# STM32MP25_CM33 register map
File version: 1.3
CPU: CM33 r0p1, little endian, MPU, FPU, vendor SysTick, 8 interrupt priority bits
Registers are 32-bit, read-write, reset 0x0 unless marked. A register's access mark holds for its fields unless they carry their own. Offsets are from the block's base; [hi:lo] are bit positions; lines under a group give offsets from that group; {n}, {i} and the like mark numbered series; 'fields as' and 'values as' point back to an identical list.

## I3C1 (part 1 of 2) — I3C register block
Base 0x40190000
Same registers: I3C2 0x401A0000, I3C3 0x401B0000, I3C4 0x46080000, I3C1_S 0x50190000, I3C2_S 0x501A0000, I3C3_S 0x501B0000, I3C4_S 0x56080000
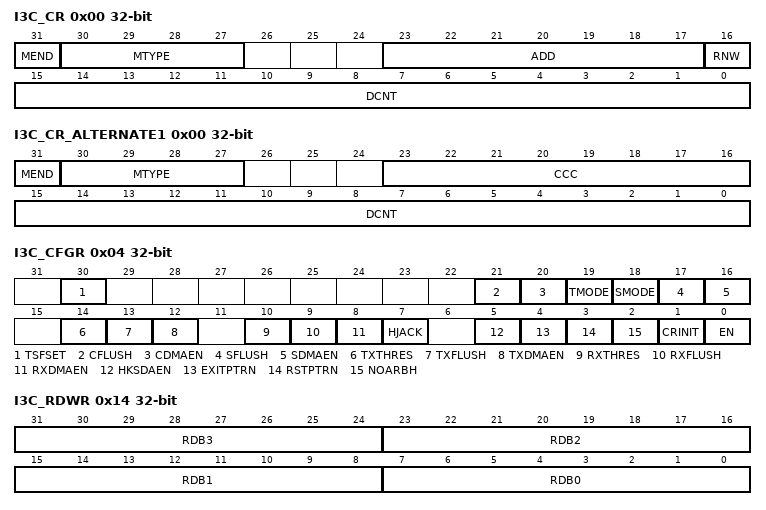
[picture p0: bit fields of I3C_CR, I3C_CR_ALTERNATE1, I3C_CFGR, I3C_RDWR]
0x00 I3C_CR wo — I3C message control register
  [31] MEND — Message end type/last message of a frame (when the I3C acts as controller)
    0=this message from controller is followed by a repeated start (Sr), before another message must be emitted; 1=this message from controller ends with a stop (P), being the last message of a frame
  [30:27] MTYPE — Message type (whatever I3C acts as controller/target) Bits[26:0] are ignored. On a CE1 error detection (ERRF = 1 in the I3C_EVR register and CODERR[3:0] = 0001 in the I3C_SER register) where a start/restart/stop is prevented from being generated, the software must use this message type for SCL “stuck at” recovery. Refer to Table 760. Bits[26:0] are ignored. If the addressed target is not responding with an ACK to a private/direct message, as an escalation stage after a failed GETSTATUS tentative, the software must program this with EXITPTRN = 1 in the I3C_CFGR register, so that an HDR exit pattern is emitted on the bus, whatever the header is ACK-ed or NACK-ed (to avoid the target to consider that the I3C bus is in HDR mode). Refer to Table760 and MIPI specification about escalation handling. Bits[23:17] (ADD[6:0]) are the emitted 7-bit dynamic address. Bit[16] (RNW) is the emitted RnW bit. Bits[15:0] (DCNT[15:0]) are the number of programmed data bytes. The transferred private message is: {S / S + 0b111_1110 + RnW = 0 + Sr/Sr+*} + 7-bit DynAddr + RnW + (8-bit Data + T)* + Sr/P. After an S (start), depending upon bit NOARBH in the I3C_CFGR register, the arbitrable header (0b111_1110 + RnW = 0) is inserted or not. Sr+*: after an Sr (repeated start), the hardware automatically inserts (0b111_1110 + RnW = 0) if needed, if it follows a previous message without ending by a P (stop). Bits[23:17] (ADD[6:0]) are the emitted 7-bit dynamic address. Bit[16] (RNW) is the emitted RnW bit. Bits[15:0] (DCNT[15:0]) are the number of programmed data bytes. The transferred direct message is: Sr + 7-bit DynAddr + RnW + (8-bit Data + T)* + Sr/P Bits[23:17] (ADD[6:0]) are the emitted 7-bit static address. Bit[16] (RNW) is the emitted RnW bit. Bits[15:0] (DCNT[15:0]) are the number of programmed data bytes. The transferred legacy Isup2/supC message is: {S / S + 0b111_1110 + RnW = 0 + Sr/Sr+*} + 7-bit StaAddr + RnW + (8-bit data + T)* + Sr/P. After an S, depending on NOARBH, the arbitrable header (0b111_1110 + RnW = 0) is inserted or not. Sr+*: after an Sr (repeated start), the hardware automatically inserts (0b111_1110 + RnW = 0) if needed (if it follows a previous message without ending by a P (stop)). Others: reserved The transferred hot-join request is {S +} 0b000_0010 addr + RnW = 0. Writing the control word initiates the hot-join request if target is allowed to do so (HJEN = 1 in the I3C_DEVR0 register), either actively after a bus idle condition via the hardware issuing a start request (SDA low) and waiting for the controller to activate SCL clock, or passively if the controller initiates a concurrent message. The transferred controller-role request is {S +} DA[6:0] + RnW = 0 (DA in the I3C_DEVR0 register) Writing the control word initiates the controller-role request if target is allowed to do so (CREN = 1 and DAVAL = 1 in the I3C_DEVR0 register), either actively after a bus idle condition via the hardware issuing a start request (SDA low) and waiting for the controller to activate SCL clock, or passively if the controller initiates a concurrent message. Bits[15:0] (DCNT[15:0]) are the number of the IBI data payload (including the first MDB), if any. The transferred IBI request is {S +} DA[6:0] + RnW = 1 + optional IBI data payload. Writing the control word initiates the IBI request if target is allowed to do so (IBIEN = 1 and DAVAL = 1 in the I3C_DEVR0.register), either actively after a bus idle condition via the hardware issuing a start request (SDA low) and waiting for the controller to activate SCL clock, or passively if the controller initiates a concurrent message. When acknowledged from controller, the transmitted IBI payload data (optional, depending upon BCR2 in the I3C_BCR register) is defined by DCNT[15:0] in the I3C_CR register and I3C_IBIDR, and must be consistently programmed vs. the IBI payload data size defined by IBIP[2:0] in the I3C_IBIDR register. Others: reserved
    0=B_0x0_WHEN_I3C_ACTS_AS_I3C_CONTROLLER (SCL clock is forced to stop until a next control word is executed); 1=B_0x1_WHEN_I3C_ACTS_AS_I3C_CONTROLLER (header message); 2=B_0x2_WHEN_I3C_ACTS_AS_I3C_CONTROLLER (private message (refer to Figure906)); 3=B_0x3_WHEN_I3C_ACTS_AS_I3C_CONTROLLER (direct message (second part of an I3C SDR direct CCC command) (refer to Figure899)); 4=B_0x4_WHEN_I3C_ACTS_AS_I3C_CONTROLLER (legacy Isup2/supC message (refer to Figure908)); 8=B_0x8_WHEN_I3C_ACTS_AS_I3C_TARGET (hot-join request (W) (refer to Figure910)); 9=B_0x9_WHEN_I3C_ACTS_AS_I3C_TARGET (controller-role request (W) (refer to Figure911)); 10=B_0xA_WHEN_I3C_ACTS_AS_I3C_TARGET (IBI (in-band interrupt) request (R) (refer to Figure909))
  [23:17] ADD — 7-bit I3C dynamic / Isup2/supC static target address (when I3C acts as controller) When I3C acts as controller, this field is used if MTYPE[3:0] = 0010 (private message), or MTYPE[3:0] = 0011 (direct message), or MTYPE[3:0] = 0100 (legacy Isup2/supC message)
  [16] RNW — Read / non-write message (when I3C acts as controller) When I3C acts as controller, this field is used if MTYPE[3:0] = 0010 (private message), or MTYPE[3:0] = 0011 (direct message), or MTYPE[3:0] = 0100 (legacy Isup2/supC message), to emit the RnW bit on the I3C bus.
    0=write message; 1=read message
  [15:0] DCNT — Count of data to transfer during a read or write message, in bytes (whatever I3C acts as controller/target) When I3C acts as controller, this field is used if MTYPE[3:0] = 0010 (private message), or MTYPE[3:0] = 0011 (direct message), or MTYPE[3:0] = 0100 (legacy Isup2/supC message), to set the number of exchanged data bytes on the bus. In case of a private or legacy Isup2/supC read/write message, this field must be non-null. When I3C acts as target, this field is used if MTYPE[3:0] = 1010 (IBI request) and if any IBI data payload (data to be transmitted if BCR2 = 1 in the I3C_BCR register), to set the number of bytes of the IBI data payload (1, 2, 3, or 4). Linear encoding up to 64Kbytes - 1 ...
    0=no data to transfer; 1=1 byte; 2=2 bytes; 0xFFFF=64 Kbytes - 1 byte
0x00 I3C_CR_ALTERNATE1 wo (alternate view of I3C_CR) — I3C message control register
  [31] MEND — Message end type/last message of a frame (when I3C acts as controller)
    0=this message from controller is followed by a repeated start (Sr), before another message must be emitted; 1=the message from the controller ends with a stop (P), being the last message of a frame
  [30:27] MTYPE — Message type (when I3C acts as controller) Bits[23:16] (CCC[7:0]) are the emitted 8-bit CCC code Bits[15:0] (DCNT[15:0]) are the number of the CCC defining bytes, or CCC sub-command bytes, or CCC data bytes. If Bit[23] = CCC[7] = 1: this is the first part of an I3C SDR direct CCC command The transferred direct CCC command (first part) message is: {S / S + 0b111_1110 +RnW = 0 / Sr+*} + (direct CCC + T) + (8-bit Data + T)* + Sr After an S (start), depending upon NOARBH in the I3C_CFGR register, the arbitrable header (0b111_1110+RnW = 0) is inserted or not. Sr+*: after an Sr (repeated start), the hardware automatically inserts (0b111_1110 + R/W). If Bit[23] = CCC[7] = 0: this is an I3C SDR broadcast CCC command (including specific ENTDAA, refer to Figure900) The transferred broadcast CCC command message is: {S / S + 0b111_1110 + RnW = 0 / Sr+*} + (broadcast CCC + T) + (8-bit Data + T)* + Sr/P After an S (start), depending on NOARBH, the arbitrable header (0b111_1110+RnW=0) is inserted or not. Sr+*: after an Sr (repeated start), the hardware automatically inserts (0b111_1110 + R/W). Others: reserved
    6=B_0x6_WHEN_I3C_ACTS_AS_I3C_CONTROLLER (broadcast/direct CCC command (refer to Table759, Figure899, Figure900, Figure901))
  [23:16] CCC — 8-bit CCC code (when I3C acts as controller) If bit[23] = CCC[7] = 1, this is the first part of an I3C SDR direct CCC command. If bit[23] = CCC[7] = 0, this is an I3C SDR broadcast CCC command (including ENTDAA).
  [15:0] DCNT — Count of related data to the CCC command to transfer as CCC defining bytes, or CCC sub-command bytes, or CCC data bytes, in bytes Linear encoding up to 64Kbytes - 1. Note: Value mandatory when emitting ENTDAA broadcast CCC (refer to Figure900). Note: Value mandatory when emitting RSTACT direct/broadcast CCC (refer to Figure901). ...
    values as I3C_CR.DCNT
0x04 I3C_CFGR — I3C configuration register
  [30] TSFSET wo — Frame transfer set (software trigger) (when I3C acts as controller) This bit can only be written. When I3C acts as I3C controller: Note: If this bit is not set, the other alternative for the software to initiate a frame transfer is to directly write the first control word register (I3C_CR) while C-FIFO is empty (CFEF = 1 in the I3C_EVR register). Then, if the first written control word is not tagged as a message end (MEND = 0 in the I3C_CR register), it causes the hardware to assert CFNFF.
    0=no action; 1=setting this bit initiates a frame transfer by causing the hardware to assert the flag CFNFF in the I3C_EVR register (C-FIFO not full and a control word is needed)
  [21] CFLUSH wo — C-FIFO flush (when I3C acts as controller) This bit can only be written.
    0=no action; 1=flush C-FIFO
  [20] CDMAEN — C-FIFO DMA request enable (when I3C acts as controller) When I3C acts as controller: - Software writes and pushes control word(s) into C-FIFO (writes I3C_CR register), as needed for a given frame - A next control word transfer can be written by software either via polling on the flag CFNFF = 1 in the I3C_EVR register, or via interrupt notification (enabled by CFNFIE = 1 in the I3C_IER register). - DMA writes and pushes control word(s) into C-FIFO (writes I3C_CR register), as needed for a given frame. - A next control word transfer is automatically written by the programmed hardware (via the asserted C-FIFO DMA request from the I3C and the programmed DMA channel).
    0=DMA mode is disabled for C-FIFO; 1=DMA mode is enabled for C-FIFO
  [19] TMODE — Transmit mode (when I3C acts as controller) When I3C acts as controller, this bit is used for the C-FIFO and TX-FIFO management vs. the emitted frame on the I3C bus. A frame transfer starts as soon as the first control word is present in C-FIFO.
    0=C-FIFO and TX-FIFO are not preloaded before starting to emit a frame transfer; 1=C-FIFO and TX-FIFO are first preloaded (also TX-FIFO if needed, depending on the frame format) before starting to emit a frame transfer. Refer to Section76.10.2 for more details.
  [18] SMODE — S-FIFO enable / status receive mode (when I3C acts as controller) When I3C acts as controller, this bit is used to enable the FIFO for the status (S-FIFO) of the exchanged message on the I3C bus. When I3C acts as target, this bit must be cleared. - Status register (I3C_SR) is used without FIFO mechanism. - There is no SCL stalling if a new status register content is not read. - Status register must be read before being overwritten by the hardware. - Must have SDMAEN = 0 in the I3C_CFGR register. - Each message status must be read. - There is SCL stalling when the S-FIFO is full and a next message status must be read. - S-FIFO overrun error is reported after the maximum SCL clock stalling time.
    0=S-FIFO is disabled; 1=S-FIFO is enabled
  [17] SFLUSH wo — S-FIFO flush (when I3C acts as controller) This bit can be written and used only when I3C acts as controller.
    0=no action; 1=flush S-FIFO
  [16] SDMAEN — S-FIFO DMA request enable (when I3C acts as controller) This bit must be cleared if SMODE = 0 in the I3C_CFGR register (S-FIFO is disabled). In other words, DMA mode cannot be used if S-FIFO is disabled. Then the status register I3C_SR can be read or not. This bit can be set or cleared if SMODE = 1 (S-FIFO is enabled). In other words, status register I3C_SR must be read for each message, either by software, or via an allocated DMA channel. - SMODE = 0: software can read the I3C_SR register after a completed frame (FCF = 1 in the I3C_EVR register) or an error (ERRF = 1 in the I3C_EVR register). Via polling on these register flags or via interrupt notification (enabled by FCIE = 1 and ERRIE=1 in the I3C_IER register). - SMODE = 1: software must read and pop a status word from S-FIFO (read I3C_SR register) after each asserted flag SFNEF = 1. Via polling on this register flag or via interrupt notification (enabled by SFNEIE = 1 in the I3C_IER register). - Must have SMODE = 1 in the I3C_CFGR register (S-FIFO enabled) - DMA reads and pops status word(s) from S-FIFO (it reads I3C_SR register) - Status word(s) are automatically read by the programmed hardware (via the asserted S-FIFO DMA request from the I3C and the programmed DMA channel).
    0=DMA mode is disabled for reading status register I3C_SR; 1=DMA mode is enabled for reading status register I3C_SR
  [14] TXTHRES — TX-FIFO threshold (whatever I3C acts as controller/target) This threshold defines, compared to the TX-FIFO level, when the TXFNFF flag is set in the I3C_EVR register (and consequently if TXDMAEN = 1 when is asserted a DMA TX request). TXFNFF is set when 1 byte must be written in TX-FIFO (in I3C_TDR). TXFNFF is set when 1 word / 4 bytes must be written in TX-FIFO (in the I3C_TDWR register). If the a number of the last transmitted data is not a multiple of 4 bytes (XDCNT[1:0] = 00 in the I3C_SR register), only the relevant 1, 2, or 3 valid LSB bytes of the last word are taken into account by the hardware, and sent on the I3C bus.
    0=1-byte threshold; 1=1-word / 4-byte threshold
  [13] TXFLUSH wo — TX-FIFO flush (whatever I3C acts as controller/target) This bit can only be written. When the I3C acts as target, this bit can be used to flush the TX-FIFO on a private read if the controller has aborted the data read (driven low the T bit), and there is/are remaining data in the TX-FIFO (ABT = 1, and XDCNT[15:0] in the I3C_SR register TGTTDCNT[15:0] in the I3C_TGTTDR register).
    0=no action; 1=flush TX-FIFO
  [12] TXDMAEN — TX-FIFO DMA request enable (whatever I3C acts as controller/target) - Software writes and pushes a data byte/word into TX-FIFO (writes I3C_TDR or I3C_TDWR register), to be transmitted over the I3C bus. - A next data byte/word must be written by the software either via polling on the flag TXFNFF = 1 or via interrupt notification (enabled by TXFNFIE = 1). - DMA writes and pushes data byte(s)/word(s) into TX-FIFO (writes I3C_TDR or I3C_TDWR register). - A next data byte/word transfer is automatically pushed by the programmed hardware (via the asserted TX-FIFO DMA request from the I3C and the programmed DMA channel).
    0=DMA mode is disabled for TX-FIFO; 1=DMA mode is enabled for TX-FIFO
  [10] RXTHRES — RX-FIFO threshold (whatever I3C acts as controller/target) This threshold defines, compared to the RX-FIFO level, when the RXFNEF flag in the I3C_EVR register is set (and consequently if RXDMAEN = 1 when is asserted a DMA RX request). RXFNEF is set when 1 byte must be read in RX-FIFO (in the I3C_RDR register). RXFNEF is set when 1 word / 4 bytes is/are to be read in RX-FIFO (in I3C_RDWR). In the case of a number of last received data being not a multiple of 4 bytes, only the relevant 1, 2 or 3 valid LSB bytes of the last word are to be considered by the software. The number of effective received data bytes is reported by XDCNT[15:0] in the I3C_SR register.
    0=1-byte threshold; 1=1-word/4-bytes threshold
  [9] RXFLUSH wo — RX-FIFO flush (whatever I3C acts as controller/target) This bit can only be written.
    0=no action; 1=flush RX-FIFO
  [8] RXDMAEN — RX-FIFO DMA request enable (whatever I3C acts as controller/target) - Software reads and pops a data byte/word from RX-FIFO (it reads I3C_RDR or I3C_RDWR register). - A next data byte/word must be read by the software either via polling flag RXFNEF = 1 in the I3C_EVR register, or via interrupt notification (enabled by RXFNEIE = 1 in the I3C_IER register). - DMA reads and pops data byte(s)/word(s) from RX-FIFO (reads I3C_RDR or I3C_RDWR register). - A next data byte/word is automatically read by the programmed hardware (via the asserted RX-FIFO DMA request from the I3C and the programmed DMA channel).
    0=DMA mode is disabled for RX-FIFO; 1=DMA mode is enabled for RX-FIFO
  [7] HJACK — Hot-join request acknowledge (when I3C acts as a controller) After the NACK, the controller continues as initially programmed (the hot-joining target is aware of the NACK and must emit another hot-join request later on). After the ACK, the controller continues as initially programmed. The software is notified by the HJ interrupt (flag HJF is set in the I3C_EVR register), and must initiate the ENTDAA sequence later on, potentially preventing other hot-join requests with a disable target events command (DISEC, with DISHJ = 1).
    0=hot-join request is not acknowledged; 1=hot-join request is acknowledged
  [5] HKSDAEN — High-keeper enable on SDA line (when I3C acts as a controller) Note: This bit can be modified only when EN = 0 in the I3C_CFGR register.
    0=High-keeper is disabled; 1=High-keeper is enabled, and the weak pull-up is effective on the T bit, instead of the open-drain class pull-up
  [4] EXITPTRN — HDR exit pattern enable (when I3C acts as a controller) This bit can be modified only when there is no on-going frame. The HDR exit pattern is sent whatever the message header {S/Sr + 0x7E addr + W} is ACK-ed or NACK-ed..
    0=HDR exit pattern is not sent after the issued message header (MTYPE[3:0]=0001 in the I3C_CR register). This is used to send the header, to test ownership of the bus when there is a suspicion of a problem after controller-role hand-off (new controller did not assert its controller-role by accessing the previous one in less than the delay defined by the activity state).; 1=HDR exit pattern is sent after the issued message header (MTYPE[3:0]=0001). This is used on a controller error detection and escalation handling, in case of a not responding target to a private message or a direct read CCC.
  [3] RSTPTRN — HDR reset pattern enable (when I3C acts as a controller) This bit can be modified only when there is no on-going frame.
    0=standard stop emitted at the end of a frame; 1=HDR reset pattern is inserted before the stop of any emitted frame that includes a RSTACT CCC command
  [2] NOARBH — No arbitrable header after a start (when I3C acts as a controller) This bit can be modified only when there is no on-going frame. - The target address is emitted directly after a start in case of a legacy Isup2/supC message or an I3C SDR private read/write message. - This is a more performing option (when the emission of the 0x7E arbitrable header is useless), but must be used only when the controller is sure that the addressed target device cannot emit concurrently an IBI or a controller-role request (to insure no misinterpretation and no potential conflict between the address emitted by the controller in open-drain mode and the same address a target device can emit after a start, for IBI or MR).
    0=An arbitrable header (0b111_1110 + RnW = 0) is emitted after a start and before a legacy Isup2/supC message or an I3C SDR private read/write message (default); 1=No arbitrable header
  [1] CRINIT — Initial controller/target role This bit can be modified only when EN=0 in the I3C_CFGR register. Once enabled by setting EN=1, the peripheral initially acts as a target. I3C does not drive SCL line and does not enable SDA pull-up, until it eventually acquires the controller role. Once enabled by setting EN=1, the peripheral initially acts as a controller. It has the I3C controller role, so drives SCL line and enables SDA pull-up, until it eventually offers the controller role to an I3C secondary controller.
    0=target role; 1=controller role
  [0] EN — I3C enable (whatever I3C acts as controller/target) - Except registers, the peripheral is under reset (partial reset). - Before clearing EN, when I3C acts as a controller, all the possible target requests must be disabled using DISEC CCC. - When I3C acts as a target, software must not disable the I3C, unless a partial reset is needed. In this state, some register fields cannot be modified (like CRINIT, HKSDAEN for the I3C_CFGR)
    0=I3C is disabled; 1=I3C is enabled
0x10 I3C_RDR ro — I3C receive data byte register
  [7:0] RDB0 — 8-bit received data on I3C bus.
0x14 I3C_RDWR ro — I3C receive data word register
  [31:24] RDB3 — 8-bit received data (latest byte on I3C bus).
  [23:16] RDB2 — 8-bit received data (next byte after RDB1 on I3C bus).
  [15:8] RDB1 — 8-bit received data (next byte after RDB0 on I3C bus).
  [7:0] RDB0 — 8-bit received data (earliest byte on I3C bus).
0x18 I3C_TDR wo — I3C transmit data byte register
  [7:0] TDB0 — 8-bit data to transmit on I3C bus.
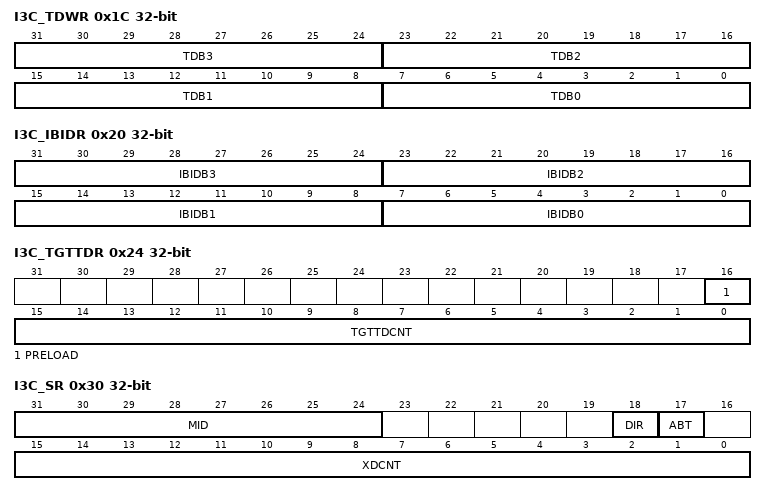
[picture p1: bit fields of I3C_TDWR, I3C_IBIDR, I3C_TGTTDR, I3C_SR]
0x1C I3C_TDWR wo — I3C transmit data word register
  [31:24] TDB3 — 8-bit transmit data (latest byte on I3C bus).
  [23:16] TDB2 — 8-bit transmit data (next byte after TDB1[7:0] on I3C bus).
  [15:8] TDB1 — 8-bit transmit data (next byte after TDB0[7:0] on I3C bus).
  [7:0] TDB0 — 8-bit transmit data (earliest byte on I3C bus)
0x20 I3C_IBIDR — I3C IBI payload data register
  [31:24] IBIDB3 — 8-bit IBI payload data (latest byte on I3C bus).
  [23:16] IBIDB2 — 8-bit IBI payload data (next byte on I3C bus after IBIDB1[7:0]).
  [15:8] IBIDB1 — 8-bit IBI payload data (next byte on I3C bus after IBIDB0[7:0]).
  [7:0] IBIDB0 — 8-bit IBI payload data (earliest byte on I3C bus, MDB[7:0] mandatory data byte).
0x24 I3C_TGTTDR — I3C target transmit configuration register
  [16] PRELOAD — Preload of the TX-FIFO (when I3C is configured as target) This bit must be written and asserted by software in the same access when is written and defined the number of bytes to preload into the TX-FIFO and to transmit. This bit is cleared by hardware when all the data bytes to transmit are loaded into the TX-FIFO.
    0=no TX-FIFO preload; 1=TX-FIFO preload
  [15:0] TGTTDCNT — Transmit data counter, in bytes (when I3C is configured as target) This bit field must be written by software in the same access when is asserted PRELOAD, in order to define the number of bytes to preload and to transmit. This bit field is updated by hardware and reports, when read, the remaining number of bytes to be loaded into the TX-FIFO.
0x30 I3C_SR ro — I3C status register
  [31:24] MID — Message identifier/counter of a given frame (when the I3C acts as controller) When I3C acts as controller, this fbitield identifies the control word message (I3C_CR) to whom the I3C_SR status register refers. First message of a frame is identified with MID[7:0] = 0. This bit field is incremented (by hardware) on the completion of a new message control word (I3C_CR) over I3C bus. This field is reset for every new frame start.
  [18] DIR — Message direction Whatever the I3C acts as controller or target, this bit indicates the direction of the related message on the I3C bus Note: ENTDAA CCC is considered as a write command.
    0=write; 1=read
  [17] ABT — A private read message is ended prematurely by the target (when the I3C acts as controller) When the I3C acts as controller, this bit indicates if the private read data transmitted by the target early terminates (the target drives T bit low earlier vs. what the controller expects in terms of programmed number of read data bytes DCNT[15:0] in the I3C_CR register).
    0=no early completion from the target; 1=early completion from the target
  [15:0] XDCNT — Data counter - When the I3C acts as controller: number of targets detected on the bus - When the I3C acts as target: number of transmitted bytes - Whatever the I3C acts as controller or target: number of data bytes read from or transmitted on the I3C bus during the message
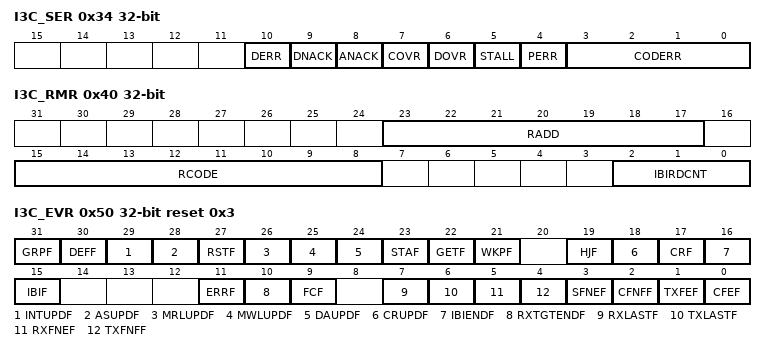
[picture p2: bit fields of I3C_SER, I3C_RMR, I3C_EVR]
0x34 I3C_SER ro — I3C status error register
  [10] DERR — Data error (when the I3C acts as controller)
    0=no detected error; 1=controller detected a data error during the controller-role hand-off procedure (GETACCCR CCC, formerly known as GETACCMST) when the received target address or/and the parity bit do no match. Active controller keeps controller-role.
  [9] DNACK — Data not acknowledged (when the I3C acts as controller) i) a legacy I2C write transfer ii) the second trial when sending dynamic address during ENTDAA procedure
    0=no detected error; 1=controller detected that a data byte is not acknowledged by a target, either during:
  [8] ANACK — Address not acknowledged (when the I3C is configured as controller) i) a legacy I2C read/write transfer ii) a direct CCC write transfer iii) the second trial of a direct CCC read transfer iv) a private read/write transfer
    0=no detected error; 1=controller detected that the static/dynamic address was not acknowledged by a target, either during:
  [7] COVR — C-FIFO underrun or S-FIFO overrun (when the I3C acts as controller) i) a C-FIFO underrun: control FIFO is empty and a restart must be emitted ii) an S-FIFO overrun: S-FIFO is full and a new message ends
    0=no detected error; 1=controller detected either:
  [6] DOVR — RX-FIFO overrun or TX-FIFO underrun i) a TX-FIFO underrun: TX-FIFO is empty and a write data byte must be transmitted ii) a RX-FIFO overrun: RX-FIFO is full and a new data byte is received
    0=no detected error; 1=whatever controller or target, hardware detected either:
  [5] STALL — SCL stall error (when the I3C acts as target)
    0=no detected error; 1=target detected that SCL was stable for more than 125 s during an I3C SDR data read (during a direct CCC read, a private read, or an IB)
  [4] PERR — Protocol error
    0=no detected error; 1=whatever controller or target, hardware detected a protocol error, as detailed in CODERR[3:0]
  [3:0] CODERR — Protocol error code/type controller detected an illegally formatted CCC controller detected that transmitted data on the bus is different from expected controller detected a not acknowledged broadcast address (0b111_1110) controller detected the new controller did not drive bus after controller-role hand-off target detected an invalid broadcast address 0b111_1110 + W target detected a parity error on a CCC code via a parity check (vs. T bit) target detected a parity error on a write data via a parity check (vs. T bit) target detected a parity error on the assigned address during dynamic address arbitration via a parity check (vs. PAR bit) target detected a 0b111_1110 + R missing after Sr during dynamic address arbitration target detected an illegally formatted CCC target detected that transmitted data on the bus is different from expected others: reserved
    0=CE0 error (transaction after sending CCC):; 1=CE1 error (monitoring error):; 2=CE2 error (no response to broadcast address):; 3=CE3 error (failed controller-role hand-off):; 8=TE0 error (invalid broadcast address 0b111_1110 + W):; 9=TE1 error (CCC code):; 10=TE2 error (write data):; 11=TE3 error (assigned address during dynamic address arbitration):; 12=TE4 error (0b111_1110 + R missing after Sr during dynamic address arbitration):; 13=TE5 error (transaction after detecting CCC):; 14=TE6 error (monitoring error):
0x40 I3C_RMR ro — I3C received message register
  [23:17] RADD — Received target address (when the I3C is configured as controller) When the I3C is configured as controller, this field logs the received dynamic address from the target during acknowledged IBI or controller-role request.
  [15:8] RCODE — Received CCC code (when the I3C is configured as target) When the I3C is configured as target, this field logs the received CCC code.
  [2:0] IBIRDCNT — IBI received payload data count (when the I3C is configured as controller) When the I3C is configured as controller, this field logs the number of data bytes effectively received in the I3C_IBIDR register.
0x50 I3C_EVR ro reset 0x3 — I3C event register
  [31] GRPF — Group addressing flag (when the I3C acts as target) When the I3C acts as target (and is typically controller-capable), this flag is asserted by hardware to indicate that the broadcast DEFGRPA CCC (define list of group addresses) has been received. Then, software can store the received data for when getting controller role. The flag is cleared when software writes 1 into the corresponding CGRPF bit in the I3C_CR register.
  [30] DEFF — DEFTGTS flag (when the I3C acts as target) When the I3C acts as target (and is typically controller capable), this flag is asserted by hardware to indicate that the broadcast DEFTGTS CCC (define list of targets) has been received. Then, software can store the received data for when getting the controller role. The flag is cleared when software writes 1 into the corresponding CDEFF bit in the I3C_CEVR register.
  [29] INTUPDF — Interrupt/controller-role/hot-join update flag (when the I3C acts as target) When the I3C acts as target, this flag is asserted by hardware to indicate that the direct or broadcast ENEC/DISEC CCC (enable/disable target events) has been received, where a target event is either an interrupt/IBI request, a controller-role request, or an hot-join request. Then, software must read respectively IBIEN, CREN, or HJEN in the I3C_DEVR0 register. The flag is cleared when software writes 1 into the corresponding CINTUPDF bit in the I3C_CEVR register.
  [28] ASUPDF — Activity state update flag (when the I3C acts as target) When the I3C acts as target, this flag is asserted by hardware to indicate that the direct or broadcast ENTASx CCC (with x = 0...3) has been received. Then, software must read AS[1:0] in the I3C_DEVR0 register. The flag is cleared when software writes 1 into the corresponding CASUPDF bit in the I3C_CEVR register.
  [27] RSTF — Reset pattern flag (when the I3C acts as target) When I3C acts as target, this flag is asserted by hardware to indicate that a reset pattern has been detected (14 SDA transitions while SCL is low, followed by repeated start, then stop). Then, when not in Stop mode, software must read RSTACT[1:0] and RSTVAL in the I3C_DEVR0 register, to know the required reset level. If RSTVAL = 1: when the RSTF is asserted (and/or the corresponding interrupt if enabled), RSTACT[1:0] in the I3C_DEVR0 register dictates the reset action to be performed by the software, if any. If RSTVAL = 0: when the RSTF is asserted (and/or the corresponding interrupt if enabled), the software must issue an I3C reset after a first detected reset pattern, and a system reset on the second one. When in Stop mode, the corresponding interrupt can be used to wake up the device. The flag is cleared when software writes 1 into the corresponding CRSTF bit in the I3C_CEVR register.
  [26] MRLUPDF — Maximum read length update flag (when the I3C acts as target) When the I3C acts as target, this flag is asserted by hardware to indicate that a direct SETMRL CCC (set max read length) has been received. Then, software must read MRL[15:0] in the I3C_MAXRLR register to get the maximum read length value. The flag is cleared when software writes 1 into the corresponding CMRLUPDF bit in the I3C_CEVR register.
  [25] MWLUPDF — Maximum write length update flag (when the I3C acts as target) When the I3C acts as target, this flag is asserted by hardware to indicate that a direct SETMWL CCC (set max write length) has been received. Then, software must read MWL[15:0] in the I3C_MAXRLR register to get the maximum write length value. The flag is cleared when software writes 1 into the corresponding CMWLUPDF bit in the I3C_CEVR register.
  [24] DAUPDF — Dynamic address update flag (when the I3C acts as target) When the I3C acts as target, this flag is asserted by hardware to indicate that a dynamic address update has been received via any of the broadcast ENTDAA, RSTDAA and direct SETNEWDA CCC. Then, software must read DA[6:0] and DAVAL in the I3C_DEVR0 register to get the dynamic address update. The flag is cleared when software writes 1 into the corresponding CDAUPDF bit in the I3C_CEVR register.
  [23] STAF — Get status flag (when the I3C acts as target) When the I3C acts as target, this flag is asserted by hardware to indicate that a direct GETSTATUS CCC of format 1 (without defining byte or with defining byte TGTSTAT) has been received. The flag is cleared when software writes 1 into the corresponding CSTAF bit in the I3C_CEVR register.
  [22] GETF — Get flag (when the I3C acts as target) When the I3C acts as target, this flag is asserted by hardware to indicate that any direct CCC of get type (GET*** CCC) except the GETSTATUS of format 1 (but including GETSTATUS of format 2) has been received. The flag is cleared when software writes 1 into the corresponding CGETF bit in the I3C_CEVR register.
  [21] WKPF — Wake-up/missed start flag (when the I3C acts as target) When the I3C acts as target, this flag is asserted by hardware to indicate that a start has been detected (an SDA falling edge followed by an SCL falling edge) but on the next SCL falling edge, the I3C kernel clock is (still) gated. Thus an I3C bus transaction may have been lost by the target. The corresponding interrupt can be used to wake up the device from a low power (Sleep or Stop) mode. The flag is cleared when software writes 1 into the corresponding CWKPF bit in the I3C_CEVR register.
  [19] HJF — Hot-join flag (when the I3C acts as controller) When the I3C acts as controller, this flag is asserted by hardware to indicate that an hot join request has been received. The flag is cleared when software writes 1 into the corresponding CHJF bit in the I3C_CEVR register.
  [18] CRUPDF — Controller-role update flag (when the I3C acts as target) When the I3C acts as target, this flag is asserted by hardware to indicate that it has now gained the controller role after the completed controller-role hand-off procedure. The flag is cleared when software writes 1 into the corresponding CCRUPDF bit in the I3C_CEVR register.
  [17] CRF — Controller-role request flag (when the I3C acts as controller) When the I3C acts as controller, this flag is asserted by hardware to indicate that a controller-role request has been acknowledged and completed (by hardware). The software must then issue a GETACCCR CCC (get accept controller role) for the controller-role hand-off procedure. The flag is cleared when software writes 1 into the corresponding CCRF bit in the I3C_CEVR register.
  [16] IBIENDF — IBI end flag (when the I3C acts as target) When the I3C acts as target, this flag is asserted by hardware to indicate that an IBI transfer has been received and completed (IBI acknowledged and IBI data bytes read by controller if any). The flag is cleared when software writes 1 into the corresponding CIBIENDF bit in the I3C_CEVR register.
  [15] IBIF — IBI flag (when the I3C acts as controller) When the I3C acts as controller, this flag is asserted by hardware to indicate that an IBI request has been received. The flag is cleared when software writes 1 into the corresponding CIBIF bit in the I3C_CEVR register.
  [11] ERRF — Flag (whatever the I3C acts as controller/target) This flag is asserted by hardware to indicate that an error occurred.Then, software must read I3C_SER to get the error type. The flag is cleared when software writes 1 into the corresponding CERRF bit in the I3C_CEVR register.
  [10] RXTGTENDF — Target-initiated read end flag (when the I3C acts as controller) When the I3C acts as controller, and only if the S-FIFO is disabled (SMODE = 0 in the I3C_CFGR register), this flag is asserted by hardware to indicate that the target has prematurely ended a read transfer. Then, software must read the status register I3C_SR to check information related to the last message and get the number of received data bytes on the prematurely read transfer (XDCNT in the I3C_SR register). The flag is cleared when software writes 1 into the corresponding CRXTGTENDF bit in the I3C_CEVR register.
  [9] FCF — Frame complete flag (whatever the I3C acts as controller/target) When the I3C acts as controller, this flag is asserted by hardware to indicate that a frame has been (normally) completed on the I3C bus, for example, when a stop is issued. When the I3C acts as target, this flag is asserted by hardware to indicate that a message addressed to/by this target has been (normally) completed on the I3C bus, for example, when a next stop or repeated start is then issued by the controller. The flag is cleared when software writes 1 into the corresponding CFCF bit in the I3C_CEVR register.
  [7] RXLASTF — Last read data byte/word flag (when the I3C acts as controller) When the I3C acts as controller, this flag is asserted by hardware to indicate that the last data byte/word (depending upon RXTHRES in the I3C_CFGR register) of a message must be read from the RX-FIFO. The flag is de-asserted by hardware when the last data byte/word of a message is read.
  [6] TXLASTF — Last written data byte/word flag (whatever the I3C acts as controller/target) This flag is asserted by hardware to indicate that the last data byte/word (depending upon TXTHRES in the I3C_CFGR register) of a message must be written to the TX-FIFO. The flag is de-asserted by hardware when the last data byte/word of a message is written.
  [5] RXFNEF — RX-FIFO not empty flag (whatever the I3C acts as controller/target) This flag is asserted/de-asserted by hardware to indicate that a data byte must/must not be read from the RX-FIFO. Note: The software must wait for RXFNEF = 1 (by polling or via the enabled interrupt) before reading from RX-FIFO (reading from I3C_RDR or I3C_RDWR, depending upon RXTHRES).
  [4] TXFNFF — TX-FIFO not full flag (whatever the I3C acts as controller/target) This flag is asserted/de-asserted by hardware to indicate that a data byte/word must/must not be written to the TX-FIFO. Note: The software must wait for TXFNFF = 1 (by polling or via the enabled interrupt) before writing to TX-FIFO (writing to I3C_TDR or I3C_TDWR, depending upon TXTHRES). Note: When the I3C acts as target, if the software intends to use the TXFNFF flag for writing into I3C_TDR/I3C_TDWR, it must have configured and set the TX-FIFO preload (write PRELOAD in the I3C_TGTTDR register).
  [3] SFNEF — S-FIFO not empty flag (when the I3C acts as controller) When the I3C acts as controller, if the S-FIFO is enabled (SMODE = 1 in the I3C_CFGR register), this flag is asserted by hardware to indicate that a status word must be read from the S-FIFO. The flag is de-asserted by hardware to indicate that a status word is not to be read from the S-FIFO.
  [2] CFNFF — C-FIFO not full flag (when the I3C acts as controller) When the I3C acts as controller, this flag is asserted by hardware to indicate that a control word must be written to the C-FIFO. The flag is de-asserted by hardware to indicate that a control word is not to be written to the C-FIFO. Note: The software must wait for CFNFF = 1 (by polling or via the enabled interrupt) before writing to C-FIFO (writing to I3C_CR).
  [1] TXFEF — TX-FIFO empty flag (whatever the I3C acts as controller/target) This flag is asserted by hardware to indicate that the TX-FIFO is empty. This flag is de-asserted by hardware to indicate that the TX-FIFO is not empty.
  [0] CFEF — C-FIFO empty flag (whatever the I3C acts as controller) This flag is asserted by hardware to indicate that the C-FIFO is empty when controller, and that the I3C_CR register contains no control word (none IBI/CR/HJ request) when target. This flag is de-asserted by hardware to indicate that the C-FIFO is not empty when controller, and that the I3C_CR register contains one control word (a pending IBI/CR/HJ request) when target. Note: When the I3C acts as controller, if the C-FIFO and TX-FIFO preload is configured (TMODE = 1 in the I3C_CFGR register), the software must wait for TXFEF = 1 and CFEF = 1 before starting a new frame transfer.
